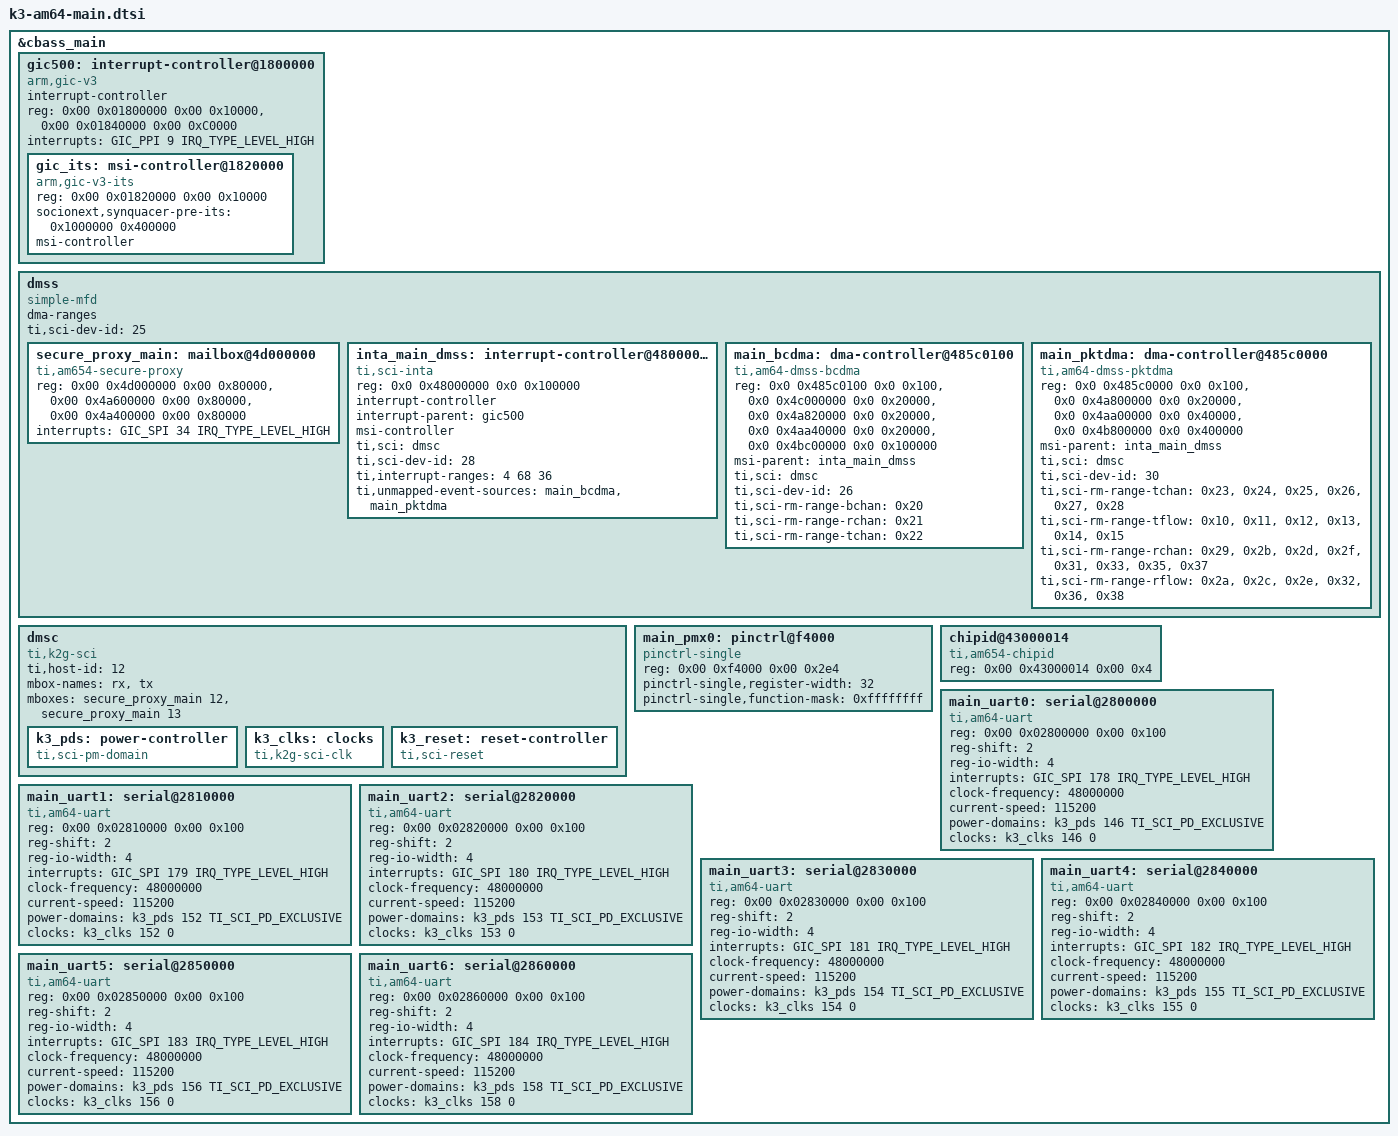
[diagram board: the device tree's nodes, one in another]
// SPDX-License-Identifier: GPL-2.0
/*
 * Device Tree Source for AM642 SoC Family Main Domain peripherals
 *
 * Copyright (C) 2020 Texas Instruments Incorporated - https://www.ti.com/
 */

&cbass_main {
	gic500: interrupt-controller@1800000 {
		compatible = "arm,gic-v3";
		#address-cells = <2>;
		#size-cells = <2>;
		ranges;
		#interrupt-cells = <3>;
		interrupt-controller;
		reg = <0x00 0x01800000 0x00 0x10000>,	/* GICD */
		      <0x00 0x01840000 0x00 0xC0000>;	/* GICR */
		/*
		 * vcpumntirq:
		 * virtual CPU interface maintenance interrupt
		 */
		interrupts = <GIC_PPI 9 IRQ_TYPE_LEVEL_HIGH>;

		gic_its: msi-controller@1820000 {
			compatible = "arm,gic-v3-its";
			reg = <0x00 0x01820000 0x00 0x10000>;
			socionext,synquacer-pre-its = <0x1000000 0x400000>;
			msi-controller;
			#msi-cells = <1>;
		};
	};

	dmss {
		compatible = "simple-mfd";
		#address-cells = <2>;
		#size-cells = <2>;
		dma-ranges;
		ranges;

		ti,sci-dev-id = <25>;

		secure_proxy_main: mailbox@4d000000 {
			compatible = "ti,am654-secure-proxy";
			#mbox-cells = <1>;
			reg-names = "target_data", "rt", "scfg";
			reg = <0x00 0x4d000000 0x00 0x80000>,
			      <0x00 0x4a600000 0x00 0x80000>,
			      <0x00 0x4a400000 0x00 0x80000>;
			interrupt-names = "rx_012";
			interrupts = <GIC_SPI 34 IRQ_TYPE_LEVEL_HIGH>;
		};

		inta_main_dmss: interrupt-controller@48000000 {
			compatible = "ti,sci-inta";
			reg = <0x0 0x48000000 0x0 0x100000>;
			interrupt-controller;
			interrupt-parent = <&gic500>;
			msi-controller;
			ti,sci = <&dmsc>;
			ti,sci-dev-id = <28>;
			ti,interrupt-ranges = <4 68 36>;
			ti,unmapped-event-sources = <&main_bcdma>, <&main_pktdma>;
		};

		main_bcdma: dma-controller@485c0100 {
			compatible = "ti,am64-dmss-bcdma";
			#address-cells = <2>;
			#size-cells = <2>;
			ranges;

			reg = <0x0 0x485c0100 0x0 0x100>,
			      <0x0 0x4c000000 0x0 0x20000>,
			      <0x0 0x4a820000 0x0 0x20000>,
			      <0x0 0x4aa40000 0x0 0x20000>,
			      <0x0 0x4bc00000 0x0 0x100000>;
			reg-names = "gcfg", "bchanrt", "rchanrt", "tchanrt", "ringrt";
			msi-parent = <&inta_main_dmss>;
			#dma-cells = <3>;

			ti,sci = <&dmsc>;
			ti,sci-dev-id = <26>;

			ti,sci-rm-range-bchan = <0x20>; /* BLOCK_COPY_CHAN */
			ti,sci-rm-range-rchan = <0x21>; /* SPLIT_TR_RX_CHAN */
			ti,sci-rm-range-tchan = <0x22>; /* SPLIT_TR_TX_CHAN */
		};

		main_pktdma: dma-controller@485c0000 {
			compatible = "ti,am64-dmss-pktdma";
			#address-cells = <2>;
			#size-cells = <2>;
			ranges;

			reg = <0x0 0x485c0000 0x0 0x100>,
			      <0x0 0x4a800000 0x0 0x20000>,
			      <0x0 0x4aa00000 0x0 0x40000>,
			      <0x0 0x4b800000 0x0 0x400000>;
			reg-names = "gcfg", "rchanrt", "tchanrt", "ringrt";
			msi-parent = <&inta_main_dmss>;
			#dma-cells = <2>;

			ti,sci = <&dmsc>;
			ti,sci-dev-id = <30>;

			ti,sci-rm-range-tchan = <0x23>, /* UNMAPPED_TX_CHAN */
						<0x24>, /* CPSW_TX_CHAN */
						<0x25>, /* SAUL_TX_0_CHAN */
						<0x26>, /* SAUL_TX_1_CHAN */
						<0x27>, /* ICSSG_0_TX_CHAN */
						<0x28>; /* ICSSG_1_TX_CHAN */
			ti,sci-rm-range-tflow = <0x10>, /* RING_UNMAPPED_TX_CHAN */
						<0x11>, /* RING_CPSW_TX_CHAN */
						<0x12>, /* RING_SAUL_TX_0_CHAN */
						<0x13>, /* RING_SAUL_TX_1_CHAN */
						<0x14>, /* RING_ICSSG_0_TX_CHAN */
						<0x15>; /* RING_ICSSG_1_TX_CHAN */
			ti,sci-rm-range-rchan = <0x29>, /* UNMAPPED_RX_CHAN */
						<0x2b>, /* CPSW_RX_CHAN */
						<0x2d>, /* SAUL_RX_0_CHAN */
						<0x2f>, /* SAUL_RX_1_CHAN */
						<0x31>, /* SAUL_RX_2_CHAN */
						<0x33>, /* SAUL_RX_3_CHAN */
						<0x35>, /* ICSSG_0_RX_CHAN */
						<0x37>; /* ICSSG_1_RX_CHAN */
			ti,sci-rm-range-rflow = <0x2a>, /* FLOW_UNMAPPED_RX_CHAN */
						<0x2c>, /* FLOW_CPSW_RX_CHAN */
						<0x2e>, /* FLOW_SAUL_RX_0/1_CHAN */
						<0x32>, /* FLOW_SAUL_RX_2/3_CHAN */
						<0x36>, /* FLOW_ICSSG_0_RX_CHAN */
						<0x38>; /* FLOW_ICSSG_1_RX_CHAN */
		};
	};

	dmsc: dmsc {
		compatible = "ti,k2g-sci";
		ti,host-id = <12>;
		mbox-names = "rx", "tx";
		mboxes= <&secure_proxy_main 12>,
			<&secure_proxy_main 13>;

		k3_pds: power-controller {
			compatible = "ti,sci-pm-domain";
			#power-domain-cells = <2>;
		};

		k3_clks: clocks {
			compatible = "ti,k2g-sci-clk";
			#clock-cells = <2>;
		};

		k3_reset: reset-controller {
			compatible = "ti,sci-reset";
			#reset-cells = <2>;
		};
	};

	main_pmx0: pinctrl@f4000 {
		compatible = "pinctrl-single";
		reg = <0x00 0xf4000 0x00 0x2e4>;
		#pinctrl-cells = <1>;
		pinctrl-single,register-width = <32>;
		pinctrl-single,function-mask = <0xffffffff>;
	};

	chipid@43000014 {
		compatible = "ti,am654-chipid";
		reg = <0x00 0x43000014 0x00 0x4>;
	};

	main_uart0: serial@2800000 {
		compatible = "ti,am64-uart", "ti,am654-uart";
		reg = <0x00 0x02800000 0x00 0x100>;
		reg-shift = <2>;
		reg-io-width = <4>;
		interrupts = <GIC_SPI 178 IRQ_TYPE_LEVEL_HIGH>;
		clock-frequency = <48000000>;
		current-speed = <115200>;
		power-domains = <&k3_pds 146 TI_SCI_PD_EXCLUSIVE>;
		clocks = <&k3_clks 146 0>;
		clock-names = "fclk";
	};

	main_uart1: serial@2810000 {
		compatible = "ti,am64-uart", "ti,am654-uart";
		reg = <0x00 0x02810000 0x00 0x100>;
		reg-shift = <2>;
		reg-io-width = <4>;
		interrupts = <GIC_SPI 179 IRQ_TYPE_LEVEL_HIGH>;
		clock-frequency = <48000000>;
		current-speed = <115200>;
		power-domains = <&k3_pds 152 TI_SCI_PD_EXCLUSIVE>;
		clocks = <&k3_clks 152 0>;
		clock-names = "fclk";
	};

	main_uart2: serial@2820000 {
		compatible = "ti,am64-uart", "ti,am654-uart";
		reg = <0x00 0x02820000 0x00 0x100>;
		reg-shift = <2>;
		reg-io-width = <4>;
		interrupts = <GIC_SPI 180 IRQ_TYPE_LEVEL_HIGH>;
		clock-frequency = <48000000>;
		current-speed = <115200>;
		power-domains = <&k3_pds 153 TI_SCI_PD_EXCLUSIVE>;
		clocks = <&k3_clks 153 0>;
		clock-names = "fclk";
	};

	main_uart3: serial@2830000 {
		compatible = "ti,am64-uart", "ti,am654-uart";
		reg = <0x00 0x02830000 0x00 0x100>;
		reg-shift = <2>;
		reg-io-width = <4>;
		interrupts = <GIC_SPI 181 IRQ_TYPE_LEVEL_HIGH>;
		clock-frequency = <48000000>;
		current-speed = <115200>;
		power-domains = <&k3_pds 154 TI_SCI_PD_EXCLUSIVE>;
		clocks = <&k3_clks 154 0>;
		clock-names = "fclk";
	};

	main_uart4: serial@2840000 {
		compatible = "ti,am64-uart", "ti,am654-uart";
		reg = <0x00 0x02840000 0x00 0x100>;
		reg-shift = <2>;
		reg-io-width = <4>;
		interrupts = <GIC_SPI 182 IRQ_TYPE_LEVEL_HIGH>;
		clock-frequency = <48000000>;
		current-speed = <115200>;
		power-domains = <&k3_pds 155 TI_SCI_PD_EXCLUSIVE>;
		clocks = <&k3_clks 155 0>;
		clock-names = "fclk";
	};

	main_uart5: serial@2850000 {
		compatible = "ti,am64-uart", "ti,am654-uart";
		reg = <0x00 0x02850000 0x00 0x100>;
		reg-shift = <2>;
		reg-io-width = <4>;
		interrupts = <GIC_SPI 183 IRQ_TYPE_LEVEL_HIGH>;
		clock-frequency = <48000000>;
		current-speed = <115200>;
		power-domains = <&k3_pds 156 TI_SCI_PD_EXCLUSIVE>;
		clocks = <&k3_clks 156 0>;
		clock-names = "fclk";
	};

	main_uart6: serial@2860000 {
		compatible = "ti,am64-uart", "ti,am654-uart";
		reg = <0x00 0x02860000 0x00 0x100>;
		reg-shift = <2>;
		reg-io-width = <4>;
		interrupts = <GIC_SPI 184 IRQ_TYPE_LEVEL_HIGH>;
		clock-frequency = <48000000>;
		current-speed = <115200>;
		power-domains = <&k3_pds 158 TI_SCI_PD_EXCLUSIVE>;
		clocks = <&k3_clks 158 0>;
		clock-names = "fclk";
	};
};
